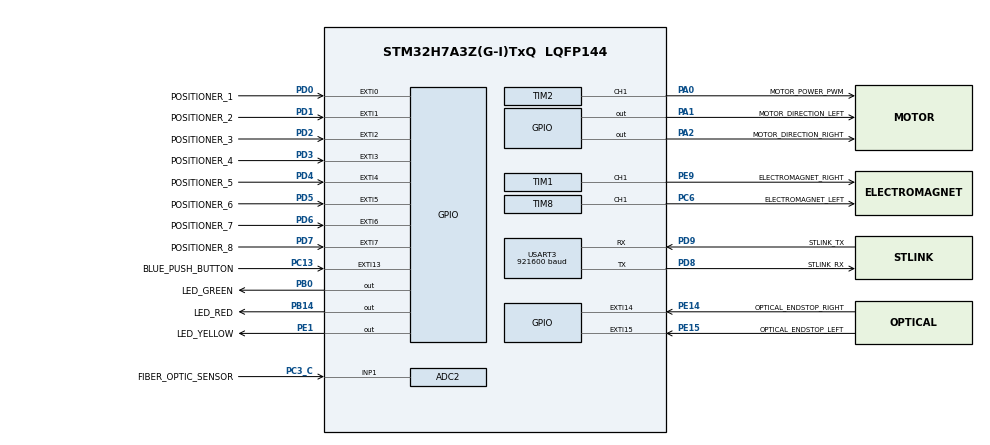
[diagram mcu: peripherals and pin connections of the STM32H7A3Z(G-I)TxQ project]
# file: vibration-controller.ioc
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ADC2.Channel-4\#ChannelRegularConversion=ADC_CHANNEL_1
ADC2.ClockPrescaler=ADC_CLOCK_ASYNC_DIV1
ADC2.ContinuousConvMode=ENABLE
ADC2.ConversionDataManagement=ADC_CONVERSIONDATA_DR
ADC2.DiscontinuousConvMode=DISABLE
ADC2.EOCSelection=ADC_EOC_SEQ_CONV
ADC2.EnableRegularConversion=ENABLE
ADC2.NbrOfConversionFlag=1
ADC2.OffsetNumber-4\#ChannelRegularConversion=ADC_OFFSET_NONE
ADC2.OffsetSignedSaturation-4\#ChannelRegularConversion=DISABLE
ADC2.Overrun=ADC_OVR_DATA_OVERWRITTEN
ADC2.OversamplingMode=ENABLE
ADC2.Rank-4\#ChannelRegularConversion=1
ADC2.Ratio=16
ADC2.RightBitShift=ADC_RIGHTBITSHIFT_4
ADC2.SamplingTime-4\#ChannelRegularConversion=ADC_SAMPLETIME_810CYCLES_5
Dma.Request0=USART3_TX
Dma.Request1=USART3_RX
Dma.USART3_RX.1.Direction=DMA_PERIPH_TO_MEMORY
Dma.USART3_RX.1.EventEnable=DISABLE
Dma.USART3_RX.1.FIFOMode=DMA_FIFOMODE_DISABLE
Dma.USART3_RX.1.Instance=DMA1_Stream0
Dma.USART3_RX.1.MemDataAlignment=DMA_MDATAALIGN_BYTE
Dma.USART3_RX.1.MemInc=DMA_MINC_ENABLE
Dma.USART3_RX.1.Mode=DMA_NORMAL
Dma.USART3_RX.1.PeriphDataAlignment=DMA_PDATAALIGN_BYTE
Dma.USART3_RX.1.PeriphInc=DMA_PINC_DISABLE
Dma.USART3_RX.1.Polarity=HAL_DMAMUX_REQ_GEN_RISING
Dma.USART3_RX.1.Priority=DMA_PRIORITY_HIGH
Dma.USART3_RX.1.RequestNumber=1
Dma.USART3_RX.1.SignalID=NONE
Dma.USART3_RX.1.SyncEnable=DISABLE
Dma.USART3_RX.1.SyncPolarity=HAL_DMAMUX_SYNC_NO_EVENT
Dma.USART3_RX.1.SyncRequestNumber=1
Dma.USART3_RX.1.SyncSignalID=NONE
Dma.USART3_TX.0.Direction=DMA_MEMORY_TO_PERIPH
Dma.USART3_TX.0.EventEnable=DISABLE
Dma.USART3_TX.0.FIFOMode=DMA_FIFOMODE_DISABLE
Dma.USART3_TX.0.Instance=DMA1_Stream1
Dma.USART3_TX.0.MemDataAlignment=DMA_MDATAALIGN_BYTE
Dma.USART3_TX.0.MemInc=DMA_MINC_ENABLE
Dma.USART3_TX.0.Mode=DMA_NORMAL
Dma.USART3_TX.0.PeriphDataAlignment=DMA_PDATAALIGN_BYTE
Dma.USART3_TX.0.PeriphInc=DMA_PINC_DISABLE
Dma.USART3_TX.0.Polarity=HAL_DMAMUX_REQ_GEN_RISING
Dma.USART3_TX.0.Priority=DMA_PRIORITY_HIGH
Dma.USART3_TX.0.RequestNumber=1
Dma.USART3_TX.0.SignalID=NONE
Dma.USART3_TX.0.SyncEnable=DISABLE
Dma.USART3_TX.0.SyncPolarity=HAL_DMAMUX_SYNC_NO_EVENT
Dma.USART3_TX.0.SyncRequestNumber=1
Dma.USART3_TX.0.SyncSignalID=NONE
Mcu.Family=STM32H7
Mcu.Name=STM32H7A3Z(G-I)TxQ
Mcu.Package=LQFP144
NVIC.ADC_IRQn=true\:0\:0\:false\:false\:true\:true\:true\:true
NVIC.DMA1_Stream0_IRQn=true\:0\:0\:false\:false\:true\:false\:true\:true
NVIC.DMA1_Stream1_IRQn=true\:0\:0\:false\:false\:true\:false\:true\:true
NVIC.EXTI0_IRQn=true\:0\:0\:true\:false\:true\:true\:true\:true
NVIC.EXTI15_10_IRQn=true\:0\:0\:true\:false\:true\:true\:true\:true
NVIC.EXTI1_IRQn=true\:0\:0\:true\:false\:true\:true\:true\:true
NVIC.EXTI2_IRQn=true\:0\:0\:true\:false\:true\:true\:true\:true
NVIC.EXTI3_IRQn=true\:0\:0\:true\:false\:true\:true\:true\:true
NVIC.EXTI4_IRQn=true\:0\:0\:true\:false\:true\:true\:true\:true
NVIC.EXTI9_5_IRQn=true\:0\:0\:true\:false\:true\:true\:true\:true
NVIC.PriorityGroup=NVIC_PRIORITYGROUP_4
NVIC.TIM7_IRQn=true\:0\:0\:false\:false\:true\:true\:true\:true
NVIC.USART3_IRQn=true\:0\:0\:false\:false\:true\:true\:true\:true
PA0.GPIO_Label=MOTOR_POWER_PWM
PA0.GPIO_ModeDefaultPP=GPIO_MODE_AF_OD
PA0.GPIO_PuPd=GPIO_PULLUP
PA0.GPIO_Speed=GPIO_SPEED_FREQ_HIGH
PA0.Signal=S_TIM2_CH1_ETR
PA1.GPIO_Label=MOTOR_DIRECTION_LEFT
PA1.GPIO_ModeDefaultOutputPP=GPIO_MODE_OUTPUT_OD
PA1.GPIO_PuPd=GPIO_NOPULL
PA1.GPIO_Speed=GPIO_SPEED_FREQ_HIGH
PA1.Signal=GPIO_Output
PA2.GPIO_Label=MOTOR_DIRECTION_RIGHT
PA2.GPIO_ModeDefaultOutputPP=GPIO_MODE_OUTPUT_OD
PA2.GPIO_PuPd=GPIO_NOPULL
PA2.GPIO_Speed=GPIO_SPEED_FREQ_HIGH
PA2.Signal=GPIO_Output
PB0.GPIO_Label=LED_GREEN
PB0.Signal=GPIO_Output
PB14.GPIO_Label=LED_RED
PB14.Signal=GPIO_Output
PC13.GPIO_Label=BLUE_PUSH_BUTTON
PC13.Signal=GPXTI13
PC3_C.GPIO_Label=FIBER_OPTIC_SENSOR
PC3_C.Mode=IN1-Single-Ended
PC3_C.Signal=ADC2_INP1
PC6.GPIO_Label=ELECTROMAGNET_LEFT
PC6.GPIO_ModeDefaultPP=GPIO_MODE_AF_OD
PC6.GPIO_Speed=GPIO_SPEED_FREQ_HIGH
PC6.Signal=S_TIM8_CH1
PD0.GPIO_Label=POSITIONER_1
PD0.Signal=GPXTI0
PD1.GPIO_Label=POSITIONER_2
PD1.Signal=GPXTI1
PD2.GPIO_Label=POSITIONER_3
PD2.Signal=GPXTI2
PD3.GPIO_Label=POSITIONER_4
PD3.Signal=GPXTI3
PD4.GPIO_Label=POSITIONER_5
PD4.Signal=GPXTI4
PD5.GPIO_Label=POSITIONER_6
PD5.Signal=GPXTI5
PD6.GPIO_Label=POSITIONER_7
PD6.Signal=GPXTI6
PD7.GPIO_Label=POSITIONER_8
PD7.Signal=GPXTI7
PD8.GPIO_Label=STLINK_RX
PD8.GPIO_Speed=GPIO_SPEED_FREQ_VERY_HIGH
PD8.Mode=Asynchronous
PD8.Signal=USART3_TX
PD9.GPIO_Label=STLINK_TX
PD9.GPIO_Speed=GPIO_SPEED_FREQ_VERY_HIGH
PD9.Mode=Asynchronous
PD9.Signal=USART3_RX
PE1.GPIO_Label=LED_YELLOW
PE1.Signal=GPIO_Output
PE14.GPIO_Label=OPTICAL_ENDSTOP_RIGHT
PE14.Signal=GPXTI14
PE15.GPIO_Label=OPTICAL_ENDSTOP_LEFT
PE15.Signal=GPXTI15
PE9.GPIO_Label=ELECTROMAGNET_RIGHT
PE9.GPIO_ModeDefaultPP=GPIO_MODE_AF_OD
PE9.GPIO_Speed=GPIO_SPEED_FREQ_HIGH
PE9.Signal=S_TIM1_CH1
PH0-OSC_IN.GPIO_Label=PH0-MCU
PH0-OSC_IN.Mode=HSE-External-Oscillator
PH0-OSC_IN.Signal=RCC_OSC_IN
PH1-OSC_OUT.GPIO_Label=PH1-MCU
PH1-OSC_OUT.Mode=HSE-External-Oscillator
PH1-OSC_OUT.Signal=RCC_OSC_OUT
ProjectManager.HeapSize=0x200
ProjectManager.StackSize=0x400
ProjectManager.TargetToolchain=Makefile
RCC.ADCFreq_Value=32500000
RCC.APB1Freq_Value=140000000
RCC.APB2Freq_Value=140000000
RCC.APB3Freq_Value=140000000
RCC.APB4Freq_Value=140000000
RCC.CDPPRE=RCC_APB3_DIV2
RCC.CDPPRE1=RCC_APB1_DIV2
RCC.CDPPRE2=RCC_APB2_DIV2
RCC.CortexFreq_Value=280000000
RCC.DIVM1=1
RCC.DIVM2=1
RCC.DIVM3=1
RCC.DIVN1=70
RCC.DIVN2=16
RCC.DIVN3=24
RCC.DIVP2=4
RCC.DIVQ1=4
RCC.HCLKFreq_Value=280000000
RCC.HSE_VALUE=8000000
RCC.PLL2FRACN=2048
RCC.PLLFRACN=0
RCC.PLLSourceVirtual=RCC_PLLSOURCE_HSE
RCC.PWR_Regulator_Voltage_Scale=PWR_REGULATOR_VOLTAGE_SCALE0
RCC.SRDPPRE=RCC_APB4_DIV2
RCC.SYSCLKFreq_VALUE=280000000
RCC.SYSCLKSource=RCC_SYSCLKSOURCE_PLLCLK
RCC.SupplySource=PWR_DIRECT_SMPS_SUPPLY
RCC.USBCLockSelection=RCC_USBCLKSOURCE_HSI48
RCC.USBFreq_Value=48000000
SH.S_TIM1_CH1.0=TIM1_CH1,PWM Generation1 CH1
SH.S_TIM2_CH1_ETR.0=TIM2_CH1,PWM Generation1 CH1
SH.S_TIM8_CH1.0=TIM8_CH1,PWM Generation1 CH1
TIM1.AutoReloadPreload=TIM_AUTORELOAD_PRELOAD_ENABLE
TIM1.Channel-PWM\ Generation1\ CH1=TIM_CHANNEL_1
TIM1.OCMode_PWM-PWM\ Generation1\ CH1=TIM_OCMODE_PWM2
TIM1.Period=1000 - 1
TIM1.Prescaler=7 - 1
TIM2.AutoReloadPreload=TIM_AUTORELOAD_PRELOAD_DISABLE
TIM2.Channel-PWM\ Generation1\ CH1=TIM_CHANNEL_1
TIM2.ClockDivision=TIM_CLOCKDIVISION_DIV1
TIM2.OC1Preload_PWM=ENABLE
TIM2.Period=100-1
TIM2.Prescaler=280-1
TIM4.Prescaler=280-1
TIM6.Period=5000
TIM6.Prescaler=280-1
TIM7.AutoReloadPreload=TIM_AUTORELOAD_PRELOAD_ENABLE
TIM7.Period=1000
TIM7.Prescaler=280-1
TIM8.AutoReloadPreload=TIM_AUTORELOAD_PRELOAD_ENABLE
TIM8.Channel-PWM\ Generation1\ CH1=TIM_CHANNEL_1
TIM8.OCMode_PWM-PWM\ Generation1\ CH1=TIM_OCMODE_PWM2
TIM8.Period=1000 - 1
TIM8.Prescaler=7 - 1
USART3.BaudRate=921600
USART3.SwapParam=ADVFEATURE_SWAP_DISABLE
USART3.VirtualMode-Asynchronous=VM_ASYNC
VP_MEMORYMAP_VS_MEMORYMAP.Mode=CurAppReg
VP_TIM2_VS_ClockSourceINT.Mode=Internal
VP_TIM4_VS_ClockSourceINT.Mode=Internal
VP_TIM6_VS_ClockSourceINT.Mode=Enable_Timer
VP_TIM7_VS_ClockSourceINT.Mode=Enable_Timer
VP_TIM8_VS_ClockSourceINT.Mode=Internal
board=NUCLEO-H7A3ZI-Q

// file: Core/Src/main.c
/* USER CODE BEGIN Header */
/**
 ******************************************************************************
 * @file           : main.c
 * @brief          : Main program body
 ******************************************************************************
 * @attention
 *
 * Copyright (c) 2024 STMicroelectronics.
 * All rights reserved.
 *
 * This software is licensed under terms that can be found in the LICENSE file
 * in the root directory of this software component.
 * If no LICENSE file comes with this software, it is provided AS-IS.
 *
 ******************************************************************************
 */
/* USER CODE END Header */
#include "main.h"
#include "adc.h"
#include "dma.h"
#include "memorymap.h"
#include "tim.h"
#include "usart.h"
#include "gpio.h"

/* USER CODE BEGIN Includes */
#include "main-app.h"
/* USER CODE END Includes */

void SystemClock_Config(void);

int main(void)
{

  /* MCU Configuration--------------------------------------------------------*/

  /* Reset of all peripherals, Initializes the Flash interface and the Systick. */
  HAL_Init();

  /* Configure the system clock */
  SystemClock_Config();

  /* Initialize all configured peripherals */
  MX_GPIO_Init();
  MX_DMA_Init();
  MX_TIM2_Init();
  MX_TIM4_Init();
  MX_TIM6_Init();
  MX_TIM7_Init();
  MX_ADC2_Init();
  MX_TIM1_Init();
  MX_TIM8_Init();
  MX_USART3_UART_Init();
  /* USER CODE BEGIN 2 */
  on_initialize();
  /* USER CODE END 2 */

  /* Infinite loop */
  /* USER CODE BEGIN WHILE */
  while (1) {
      on_loop_tick();
    /* USER CODE END WHILE */

  }
}

void SystemClock_Config(void)
{
  RCC_OscInitTypeDef RCC_OscInitStruct = {0};
  RCC_ClkInitTypeDef RCC_ClkInitStruct = {0};

  /*AXI clock gating */
  RCC->CKGAENR = 0xFFFFFFFF;

  /** Supply configuration update enable
  */
  HAL_PWREx_ConfigSupply(PWR_DIRECT_SMPS_SUPPLY);

  /** Configure the main internal regulator output voltage
  */
  __HAL_PWR_VOLTAGESCALING_CONFIG(PWR_REGULATOR_VOLTAGE_SCALE0);

  while(!__HAL_PWR_GET_FLAG(PWR_FLAG_VOSRDY)) {}

  /** Initializes the RCC Oscillators according to the specified parameters
  * in the RCC_OscInitTypeDef structure.
  */
  RCC_OscInitStruct.OscillatorType = RCC_OSCILLATORTYPE_HSE;
  RCC_OscInitStruct.HSEState = RCC_HSE_ON;
  RCC_OscInitStruct.PLL.PLLState = RCC_PLL_ON;
  RCC_OscInitStruct.PLL.PLLSource = RCC_PLLSOURCE_HSE;
  RCC_OscInitStruct.PLL.PLLM = 1;
  RCC_OscInitStruct.PLL.PLLN = 70;
  RCC_OscInitStruct.PLL.PLLP = 2;
  RCC_OscInitStruct.PLL.PLLQ = 4;
  RCC_OscInitStruct.PLL.PLLR = 2;
  RCC_OscInitStruct.PLL.PLLRGE = RCC_PLL1VCIRANGE_3;
  RCC_OscInitStruct.PLL.PLLVCOSEL = RCC_PLL1VCOWIDE;
  RCC_OscInitStruct.PLL.PLLFRACN = 0;
  if (HAL_RCC_OscConfig(&RCC_OscInitStruct) != HAL_OK)
  {
    Error_Handler();
  }

  /** Initializes the CPU, AHB and APB buses clocks
  */
  RCC_ClkInitStruct.ClockType = RCC_CLOCKTYPE_HCLK|RCC_CLOCKTYPE_SYSCLK
                              |RCC_CLOCKTYPE_PCLK1|RCC_CLOCKTYPE_PCLK2
                              |RCC_CLOCKTYPE_D3PCLK1|RCC_CLOCKTYPE_D1PCLK1;
  RCC_ClkInitStruct.SYSCLKSource = RCC_SYSCLKSOURCE_PLLCLK;
  RCC_ClkInitStruct.SYSCLKDivider = RCC_SYSCLK_DIV1;
  RCC_ClkInitStruct.AHBCLKDivider = RCC_HCLK_DIV1;
  RCC_ClkInitStruct.APB3CLKDivider = RCC_APB3_DIV2;
  RCC_ClkInitStruct.APB1CLKDivider = RCC_APB1_DIV2;
  RCC_ClkInitStruct.APB2CLKDivider = RCC_APB2_DIV2;
  RCC_ClkInitStruct.APB4CLKDivider = RCC_APB4_DIV2;

  if (HAL_RCC_ClockConfig(&RCC_ClkInitStruct, FLASH_LATENCY_6) != HAL_OK)
  {
    Error_Handler();
  }
}

void Error_Handler(void)
{
  __disable_irq();
  while (1) {
  }
}
